# f28e12x_adc_lite_regs register map
Vendor: Texas Instruments
Peripheral module from a debugger description file (folder C2000).
Address unit: 16 bits
Registers are 32-bit, read-write, no defined reset value unless marked. A register's access mark holds for its fields unless they carry their own. Offsets are as the file gives them; lines under a group give offsets from that group; [hi:lo] are bit positions; {n}, {i} and the like mark numbered series; 'fields as' and 'values as' point back to an identical list; <NAME> marks a mode.

## ADC_LITE_REGS — ADC LITE Registers
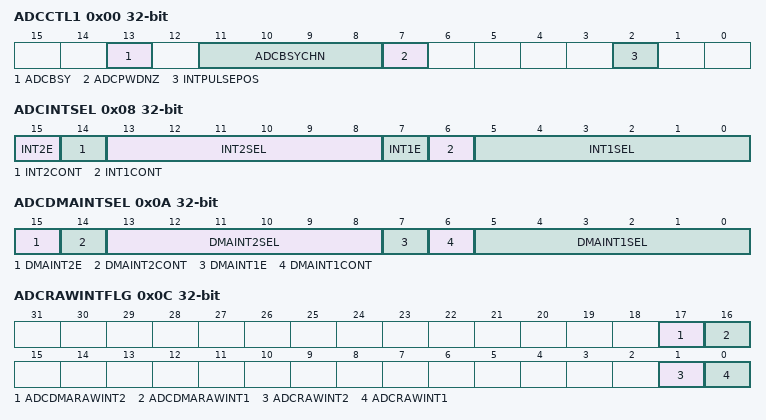
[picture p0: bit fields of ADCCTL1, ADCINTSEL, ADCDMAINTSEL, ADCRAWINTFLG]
0x00 ADCCTL1 access per field — ADC Control 1 Register
  [13] ADCBSY ro — ADC Busy
  [11:8] ADCBSYCHN ro — ADC Busy Channel
  [7] ADCPWDNZ rw — ADC Power Down
  [2] INTPULSEPOS rw — ADC Interrupt Pulse Position
0x02 ADCCTL2 — ADC Control 2 Register
  [3:0] PRESCALE — ADC Clock Prescaler
0x08 ADCINTSEL — ADC Interrupt 1, 2, 3 and 4 Selection Register
  [15] INT2E — ADCINT2 Interrupt Enable
  [14] INT2CONT — ADCINT2 Continue to Interrupt Mode
  [13:8] INT2SEL — ADCINT2 EOC Source Select
  [7] INT1E — ADCINT1 Interrupt Enable
  [6] INT1CONT — ADCINT1 Continue to Interrupt Mode
  [5:0] INT1SEL — ADCINT1 EOC Source Select
0x0A ADCDMAINTSEL — ADC DMA Interrupt 1, 2, 3 and 4 Selection Register
  [15] DMAINT2E — ADCDMAINT2 Interrupt Enable
  [14] DMAINT2CONT — ADCDMAINT2 Continue to Interrupt Mode
  [13:8] DMAINT2SEL — ADCDMAINT2 EOC Source Select
  [7] DMAINT1E — ADCDMAINT1 Interrupt Enable
  [6] DMAINT1CONT — ADCDMAINT1 Continue to Interrupt Mode
  [5:0] DMAINT1SEL — ADCDMAINT1 EOC Source Select
0x0C ADCRAWINTFLG ro — ADC Raw Interrupt Flag Register
  [17] ADCDMARAWINT2 — ADC DMA Raw Interrupt 2 Flag
  [16] ADCDMARAWINT1 — ADC DMA Raw Interrupt 1 Flag
  [1] ADCRAWINT2 — ADC Raw Interrupt 2 Flag
  [0] ADCRAWINT1 — ADC Raw Interrupt 1 Flag
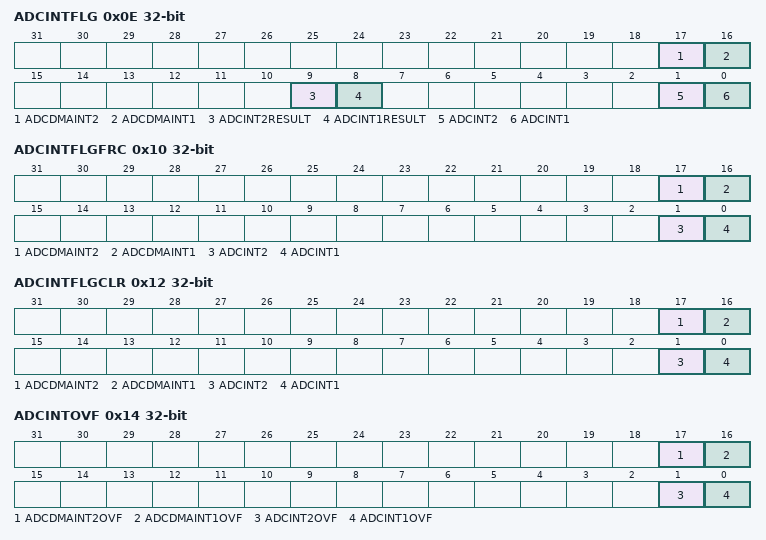
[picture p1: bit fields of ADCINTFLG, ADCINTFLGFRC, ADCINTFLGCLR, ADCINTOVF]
0x0E ADCINTFLG ro — ADC Interrupt Flag Register
  [17] ADCDMAINT2 — ADC DMA Interrupt 2 Flag
  [16] ADCDMAINT1 — ADC DMA Interrupt 1 Flag
  [9] ADCINT2RESULT — ADC Interrupt 2 Results Ready
  [8] ADCINT1RESULT — ADC Interrupt 1 Results Ready
  [1] ADCINT2 — ADC Interrupt 2 Flag
  [0] ADCINT1 — ADC Interrupt 1 Flag
0x10 ADCINTFLGFRC — ADC Interrupt Flag Force Register
  [17] ADCDMAINT2 — ADC DMA Interrupt 2 Flag Force
  [16] ADCDMAINT1 — ADC DMA Interrupt 1 Flag Force
  [1] ADCINT2 — ADC Interrupt 2 Flag Force
  [0] ADCINT1 — ADC Interrupt 1 Flag Force
0x12 ADCINTFLGCLR — ADC Interrupt Flag Clear Register
  [17] ADCDMAINT2 — ADC DMA Interrupt 2 Flag Clear
  [16] ADCDMAINT1 — ADC DMA Interrupt 1 Flag Clear
  [1] ADCINT2 — ADC Interrupt 2 Flag Clear
  [0] ADCINT1 — ADC Interrupt 1 Flag Clear
0x14 ADCINTOVF ro — ADC Interrupt Overflow Register
  [17] ADCDMAINT2OVF — ADC DMA Interrupt 2 Overflow Flags
  [16] ADCDMAINT1OVF — ADC DMA Interrupt 1 Overflow Flags
  [1] ADCINT2OVF — ADC Interrupt 2 Overflow Flags
  [0] ADCINT1OVF — ADC Interrupt 1 Overflow Flags
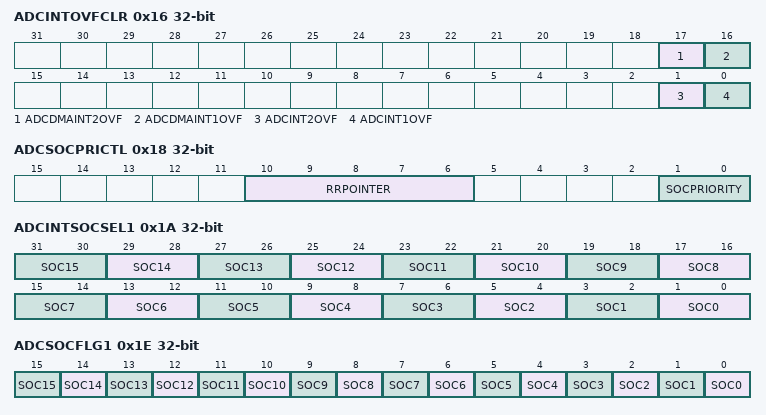
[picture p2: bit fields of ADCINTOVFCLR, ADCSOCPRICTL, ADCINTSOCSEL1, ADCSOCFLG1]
0x16 ADCINTOVFCLR — ADC Interrupt Overflow Clear Register
  [17] ADCDMAINT2OVF — ADC DMA Interrupt 2 Overflow Clear Bits
  [16] ADCDMAINT1OVF — ADC DMA Interrupt 1 Overflow Clear Bits
  [1] ADCINT2OVF — ADC Interrupt 2 Overflow Clear Bits
  [0] ADCINT1OVF — ADC Interrupt 1 Overflow Clear Bits
0x18 ADCSOCPRICTL access per field — ADC SOC Priority Control Register
  [10:6] RRPOINTER ro — Round Robin Pointer
  [1:0] SOCPRIORITY rw
0x1A ADCINTSOCSEL1 — ADC Interrupt SOC Selection 1 Register
  [2n+1:2n] SOC{n} (n=0..15) — SOC{n} ADC Interrupt Trigger Select
0x1E ADCSOCFLG1 ro — ADC SOC Flag 1 Register
  [n] SOC{n} (n=0..15) — SOC{n} Start of Conversion Flag
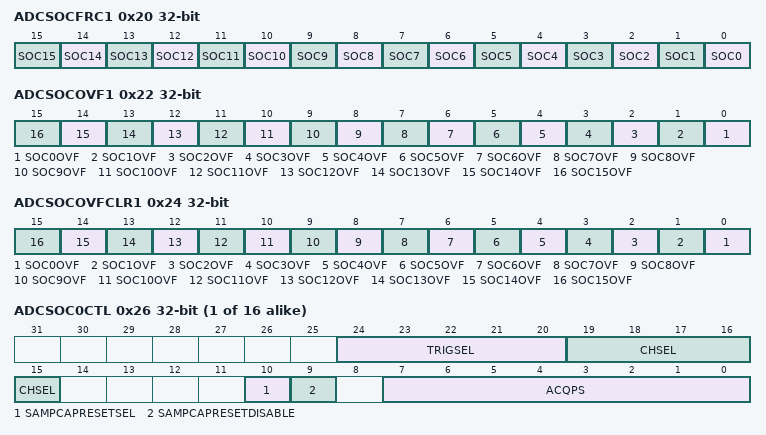
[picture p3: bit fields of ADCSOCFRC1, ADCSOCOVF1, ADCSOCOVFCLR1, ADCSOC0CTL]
0x20 ADCSOCFRC1 — ADC SOC Force 1 Register
  [n] SOC{n} (n=0..15) — SOC{n} Force Start of Conversion Bit
0x22 ADCSOCOVF1 ro — ADC SOC Overflow 1 Register
  [n] SOC{n}OVF (n=0..15) — SOC{n} Start of Conversion Overflow Flag
0x24 ADCSOCOVFCLR1 — ADC SOC Overflow Clear 1 Register
  [n] SOC{n}OVF (n=0..15) — SOC{n} Clear Start of Conversion Overflow Bit
{0x26+2i} ADCSOC{i}CTL (i=0..15) — ADC SOC{i} Control Register
  [24:20] TRIGSEL — SOC{i} Trigger Source Select
  [19:15] CHSEL — SOC{i} Channel Select
  [10] SAMPCAPRESETSEL — SOC{i} Sample Cap Reset Select
  [9] SAMPCAPRESETDISABLE — SOC{i} Sample Cap Reset Enable
  [7:0] ACQPS — SOC{i} Acquisition Prescale
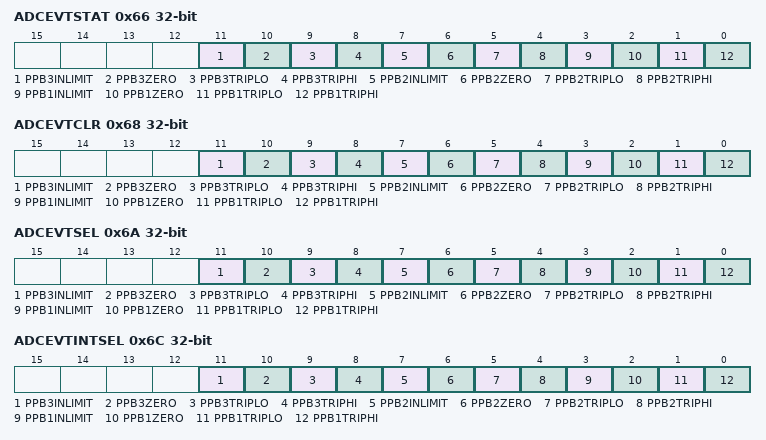
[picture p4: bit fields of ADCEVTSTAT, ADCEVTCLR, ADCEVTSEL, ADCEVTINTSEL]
0x66 ADCEVTSTAT ro — ADC Event Status Register
  [11] PPB3INLIMIT — Post Processing Block 3 Within trip limit Flag
  [10] PPB3ZERO — Post Processing Block 3 Zero Crossing Flag
  [9] PPB3TRIPLO — Post Processing Block 3 Trip Low Flag
  [8] PPB3TRIPHI — Post Processing Block 3 Trip High Flag
  [7] PPB2INLIMIT — Post Processing Block 2 Within trip limit Flag
  [6] PPB2ZERO — Post Processing Block 2 Zero Crossing Flag
  [5] PPB2TRIPLO — Post Processing Block 2 Trip Low Flag
  [4] PPB2TRIPHI — Post Processing Block 2 Trip High Flag
  [3] PPB1INLIMIT — Post Processing Block 1 Within trip limit Flag
  [2] PPB1ZERO — Post Processing Block 1 Zero Crossing Flag
  [1] PPB1TRIPLO — Post Processing Block 1 Trip Low Flag
  [0] PPB1TRIPHI — Post Processing Block 1 Trip High Flag
0x68 ADCEVTCLR — ADC Event Clear Register
  [11] PPB3INLIMIT — Post Processing Block 3 Within trip limit flag Clear
  [10] PPB3ZERO — Post Processing Block 3 Zero Crossing Clear
  [9] PPB3TRIPLO — Post Processing Block 3 Trip Low Clear
  [8] PPB3TRIPHI — Post Processing Block 3 Trip High Clear
  [7] PPB2INLIMIT — Post Processing Block 2 Within trip limit flag Clear
  [6] PPB2ZERO — Post Processing Block 2 Zero Crossing Clear
  [5] PPB2TRIPLO — Post Processing Block 2 Trip Low Clear
  [4] PPB2TRIPHI — Post Processing Block 2 Trip High Clear
  [3] PPB1INLIMIT — Post Processing Block 1 Within trip limit flag Clear
  [2] PPB1ZERO — Post Processing Block 1 Zero Crossing Clear
  [1] PPB1TRIPLO — Post Processing Block 1 Trip Low Clear
  [0] PPB1TRIPHI — Post Processing Block 1 Trip High Clear
0x6A ADCEVTSEL — ADC Event Selection Register
  [11] PPB3INLIMIT — Post Processing Block 3 Within trip limit event enable
  [10] PPB3ZERO — Post Processing Block 3 Zero Crossing Event Enable
  [9] PPB3TRIPLO — Post Processing Block 3 Trip Low Event Enable
  [8] PPB3TRIPHI — Post Processing Block 3 Trip High Event Enable
  [7] PPB2INLIMIT — Post Processing Block 2 Within trip limit event enable
  [6] PPB2ZERO — Post Processing Block 2 Zero Crossing Event Enable
  [5] PPB2TRIPLO — Post Processing Block 2 Trip Low Event Enable
  [4] PPB2TRIPHI — Post Processing Block 2 Trip High Event Enable
  [3] PPB1INLIMIT — Post Processing Block 1 Within trip limit event enable
  [2] PPB1ZERO — Post Processing Block 1 Zero Crossing Event Enable
  [1] PPB1TRIPLO — Post Processing Block 1 Trip Low Event Enable
  [0] PPB1TRIPHI — Post Processing Block 1 Trip High Event Enable
0x6C ADCEVTINTSEL — ADC Event Interrupt Selection Register
  [11] PPB3INLIMIT — Post Processing Block 3 Within trip limit interrupt enable
  [10] PPB3ZERO — Post Processing Block 3 Zero Crossing Interrupt Enable
  [9] PPB3TRIPLO — Post Processing Block 3 Trip Low Interrupt Enable
  [8] PPB3TRIPHI — Post Processing Block 3 Trip High Interrupt Enable
  [7] PPB2INLIMIT — Post Processing Block 2 Within trip limit interrupt enable
  [6] PPB2ZERO — Post Processing Block 2 Zero Crossing Interrupt Enable
  [5] PPB2TRIPLO — Post Processing Block 2 Trip Low Interrupt Enable
  [4] PPB2TRIPHI — Post Processing Block 2 Trip High Interrupt Enable
  [3] PPB1INLIMIT — Post Processing Block 1 Within trip limit interrupt enable
  [2] PPB1ZERO — Post Processing Block 1 Zero Crossing Interrupt Enable
  [1] PPB1TRIPLO — Post Processing Block 1 Trip Low Interrupt Enable
  [0] PPB1TRIPHI — Post Processing Block 1 Trip High Interrupt Enable
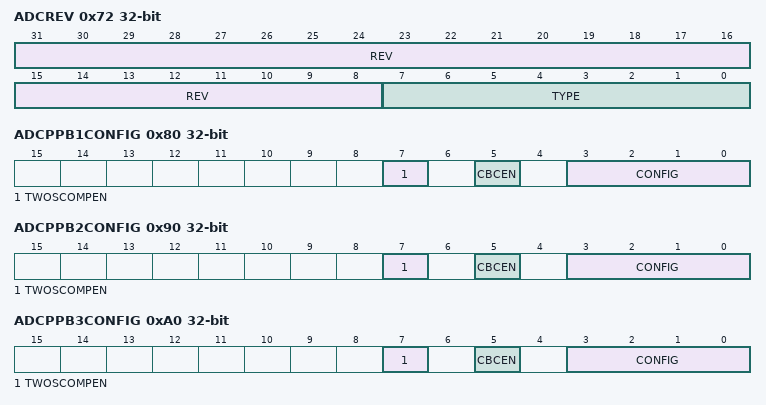
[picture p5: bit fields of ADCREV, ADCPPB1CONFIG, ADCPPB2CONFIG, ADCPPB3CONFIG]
0x72 ADCREV ro — ADC Revision Register
  [31:8] REV — ADC Revision
  [7:0] TYPE — ADC Type
0x74 ADCOFFTRIM — ADC Offset Trim Register 1
  [7:0] OFFTRIM — ADC Offset Trim
0x80 ADCPPB1CONFIG — ADC PPB{#} Config Register
  [7] TWOSCOMPEN — ADC Post Processing Block {#} Two's Complement Enable
  [5] CBCEN — Cycle By Cycle Enable
  [3:0] CONFIG — ADC Post Processing Block {#} Configuration
{0x74+0x10*i} ADCPPB{i}OFFCAL (i=1..3) — ADC PPB{i} Offset Calibration Register
  [5:0] OFFCAL — ADC Post Processing Block Offset Correction
{0x76+0x10*i} ADCPPB{i}OFFREF (i=1..3) — ADC PPB{i} Offset Reference Register
  [11:0] OFFREF — ADC Post Processing Block {i} Offset Reference
{0x78+0x10*i} ADCPPB{i}TRIPHI (i=1..3) — ADC PPB{i} Trip High Register
  [15:0] LIMITHI — ADC Post Processing Block {i} Trip High Limit
{0x7A+0x10*i} ADCPPB{i}TRIPLO (i=1..3) — ADC PPB{i} Trip Low/Trigger Time Stamp Register
  [15:0] LIMITLO — ADC Post Processing Block {i} Trip Low Limit
0x90 ADCPPB2CONFIG — ADC PPB{#} Config Register
  fields as ADCPPB1CONFIG
0xA0 ADCPPB3CONFIG — ADC PPB{#} Config Register
  fields as ADCPPB1CONFIG
0xC0 ADCINTCYCLE — ADC Early Interrupt Generation Cycle
  [5:0] DELAY — Delay from ADCSOC fall edge to early interrupt generation.
0xC2 ADCINLTRIM1 — ADC Linearity Trim 1 Register
  [31:0] INLTRIM31TO0 — ADC Linearity Trim Bits 31-0
0xC4 ADCINLTRIM2 — ADC Linearity Trim 2 Register
  [31:0] INLTRIM63TO32 — ADC Linearity Trim Bits 63-32
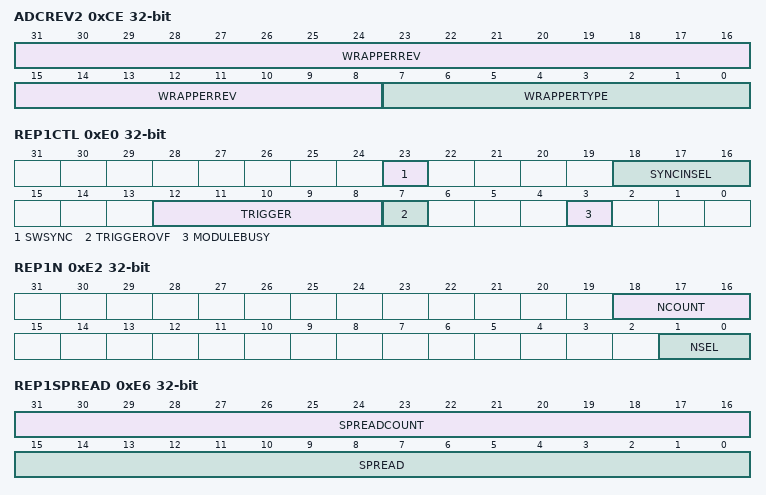
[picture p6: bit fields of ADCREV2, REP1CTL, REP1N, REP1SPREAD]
0xCE ADCREV2 ro — ADC Wrapper Revision Register
  [31:8] WRAPPERREV — ADC Wrapper Revision
  [7:0] WRAPPERTYPE — ADC Wrapper Type
0xE0 REP1CTL access per field — ADC Trigger Repeater 1 Control Register
  [23] SWSYNC rw — ADC Trigger Repeater 1 Software Sync.
  [18:16] SYNCINSEL rw — ADC Trigger Repeater 1 Sync. In Select
  [12:8] TRIGGER rw — ADC Trigger Repeater 1 Trigger Select
  [7] TRIGGEROVF rw — ADC Trigger Repeater 1 Oversampled Trigger Overflow
  [3] MODULEBUSY ro — ADC Trigger Repeater 1 Module Busy
0xE2 REP1N access per field — ADC Trigger Repeater 1 N Select Register
  [18:16] NCOUNT ro — ADC Trigger Repeater 1 Trigger Counter
  [1:0] NSEL rw — ADC Trigger Repeater 1 Trigger Number Selection
0xE6 REP1SPREAD access per field — ADC Trigger Repeater 1 Spread Select Register
  [31:16] SPREADCOUNT ro — ADC Trigger Repeater 1 Spread Delay Status
  [15:0] SPREAD rw — ADC Trigger Repeater 1 Spread Delay Configuration
0xE8 REP1FRC — ADC Trigger Repeater 1 Software Force Register
  [0] SWFRC — ADC Trigger Repeater 1 Software Force
0x100 ADCPPB1LIMIT — ADC PPB1Conversion Count Limit Register
  [1:0] LIMIT — Post Processing Block 1 Limit
0x102 ADCPPBP1PCOUNT ro — ADC PPB1 Partial Conversion Count Register
  [2:0] PCOUNT — Post Processing Block 1 Partial Count
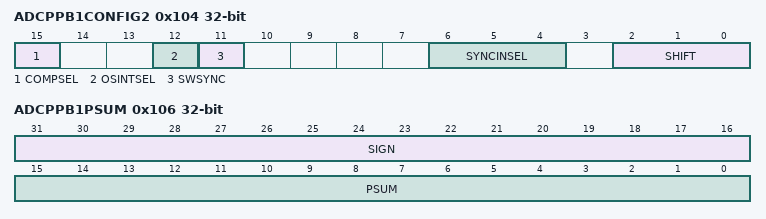
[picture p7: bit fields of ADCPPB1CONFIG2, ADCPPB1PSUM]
0x104 ADCPPB1CONFIG2 — ADC PPB1 Sum Shift Register
  [15] COMPSEL — Post Processing Block 1 Compare Source Select
  [12] OSINTSEL — Post Processing Block 1 Interrupt Source Select
  [11] SWSYNC — Post Processing Block 1 Software Force Sync.
  [6:4] SYNCINSEL — Post Processing Block 1 Sync. Input Select
  [2:0] SHIFT — Post Processing Block 1 Right Shift
0x106 ADCPPB1PSUM ro — ADC PPB1 Partial Sum Register
  [31:16] SIGN — Sign Extended Bits
  [15:0] PSUM — Post Processing Block 1 Oversampling Partial Sum
